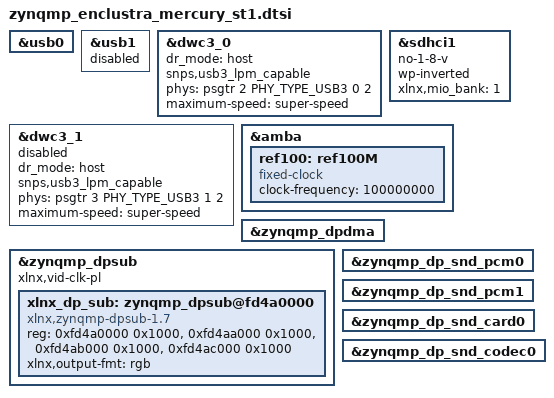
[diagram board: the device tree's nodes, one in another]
#include <dt-bindings/phy/phy.h>

&usb0 {
	status = "okay";
};

&usb1 {
	status = "disabled";
};

&dwc3_0 {
	status = "okay";
	dr_mode = "host";
	snps,usb3_lpm_capable;
	phy-names = "usb3-phy";
	phys = <&psgtr 2 PHY_TYPE_USB3 0 2>;
	maximum-speed = "super-speed";
};

&dwc3_1 {
	status = "disabled";
	dr_mode = "host";
	snps,usb3_lpm_capable;
	phy-names = "usb3-phy";
	phys = <&psgtr 3 PHY_TYPE_USB3 1 2>;
	maximum-speed = "super-speed";
};

/* SD1 with level shifter */
&sdhci1 {
	status = "okay";
	no-1-8-v;	/* for 1.0 silicon */
	wp-inverted;
	xlnx,mio_bank = <1>;
};

&amba {
	ref100: ref100M {
		compatible = "fixed-clock";
		#clock-cells = <0>;
		clock-frequency = <100000000>;
	};
};

&zynqmp_dpdma {
	status = "okay";
};

&zynqmp_dpsub {
	status = "okay";
	xlnx,vid-clk-pl;
	
	xlnx_dp_sub: zynqmp_dpsub@fd4a0000 {
		compatible = "xlnx,zynqmp-dpsub-1.7";
		reg = <0xfd4a0000 0x1000>, 
              <0xfd4aa000 0x1000>, 
              <0xfd4ab000 0x1000>, 
              <0xfd4ac000 0x1000>;
		reg-names = "dp", "blend", "av_buf", "aud";
		xlnx,output-fmt = "rgb";
	};
};

&zynqmp_dp_snd_pcm0 {
    status = "okay";
};

&zynqmp_dp_snd_pcm1 {
    status = "okay";
};

&zynqmp_dp_snd_card0 {
    status = "okay";
};

&zynqmp_dp_snd_codec0 {
    status = "okay";
};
